AUTOSAR XML (schema 4-2-2)
package /EB/SoftwareComponents
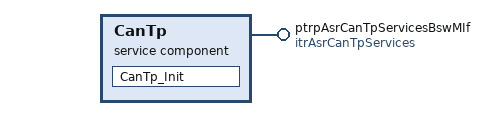
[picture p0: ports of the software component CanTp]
  service sw component type CanTp: category=ASR_Interfaces
    provide port ptrpAsrCanTpServicesBswMIf: provided-interface=itrAsrCanTpServices
    behavior CanTp_IB: handle-termination-and-restart=NO-SUPPORT
      runnable CanTp_Init
package /EB/TriggerInterfaces
  trigger interface itrAsrCanTpServices
    trigger CanTp_Init: trigger-period={cse-code=1000, cse-code-factor=0}
  trigger interface itrIoHwAbServices
